# STM32G534xx register map
File version: 1.0
Registers are 32-bit, read-write, reset 0x0 unless marked. A register's access mark holds for its fields unless they carry their own. Offsets are from the block's base; [hi:lo] are bit positions; {n}, {i} and the like mark numbered series.

## DTS — Digital temperature sensor (DTS)
Base 0x40008C00
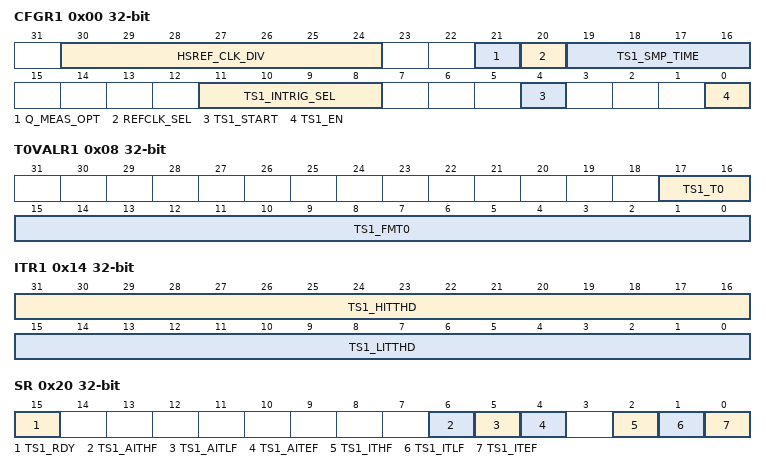
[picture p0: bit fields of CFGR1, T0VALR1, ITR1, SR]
0x00 CFGR1 — Temperature sensor configuration register 1
  [30:24] HSREF_CLK_DIV, [21] Q_MEAS_OPT, [20] REFCLK_SEL, [19:16] TS1_SMP_TIME, [11:8] TS1_INTRIG_SEL, [4] TS1_START, [0] TS1_EN
0x08 T0VALR1 ro — Temperature sensor T0 value register 1
  [17:16] TS1_T0, [15:0] TS1_FMT0
0x10 RAMPVALR ro — Temperature sensor ramp value register
  [15:0] TS1_RAMP_COEFF
0x14 ITR1 — Temperature sensor interrupt threshold register 1
  [31:16] TS1_HITTHD, [15:0] TS1_LITTHD
0x1C DR — Temperature sensor data register
  [15:0] TS1_MFREQ
0x20 SR ro — Temperature sensor status register
  [15] TS1_RDY, [6] TS1_AITHF, [5] TS1_AITLF, [4] TS1_AITEF, [2] TS1_ITHF, [1] TS1_ITLF, [0] TS1_ITEF
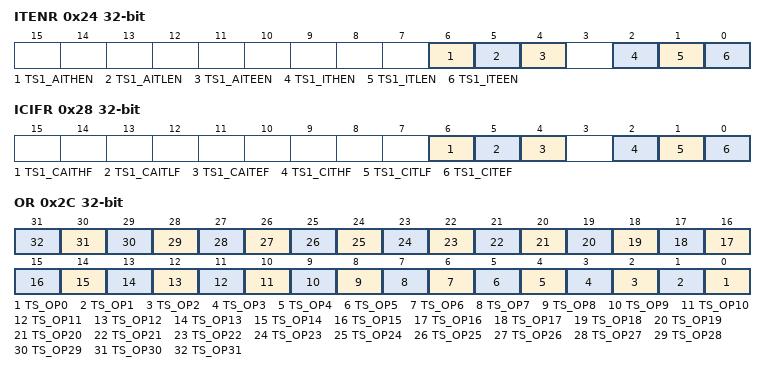
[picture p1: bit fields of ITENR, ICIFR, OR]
0x24 ITENR — Temperature sensor interrupt enable register
  [6] TS1_AITHEN, [5] TS1_AITLEN, [4] TS1_AITEEN, [2] TS1_ITHEN, [1] TS1_ITLEN, [0] TS1_ITEEN
0x28 ICIFR — Temperature sensor clear interrupt flag register
  [6] TS1_CAITHF, [5] TS1_CAITLF, [4] TS1_CAITEF, [2] TS1_CITHF, [1] TS1_CITLF, [0] TS1_CITEF
0x2C OR — Temperature sensor option register
  [n] TS_OP{n} (n=0..31) — general purpose option bits

## FDCAN_CONFIG — FD Controller Area Network Configuration
Base 0x4000A100
0x00 CKDIV — FDCAN CFG clock divider register
  [3:0] PDIV — input clock divider

## CRC — Cyclic redundancy check calculation unit (CRC)
Base 0x40023000
0x00 DR — CRC data register
  [31:0] DR — Data register bits
0x04 IDR — CRC independent data register
  [31:0] IDR — General-purpose 32-bit data register bits
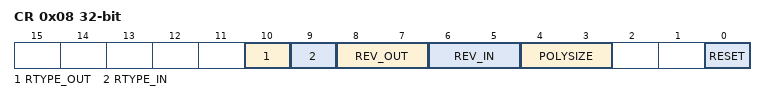
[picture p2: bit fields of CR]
0x08 CR — CRC control register
  [10] RTYPE_OUT — Reverse type output
  [9] RTYPE_IN — Reverse type input
  [8:7] REV_OUT — Reverse output data
  [6:5] REV_IN — Reverse input data
  [4:3] POLYSIZE — Polynomial size
  [0] RESET — RESET bit
0x10 INIT — CRC initial value
  [31:0] CRC_INIT — Programmable initial CRC value
0x14 POL — CRC polynomial
  [31:0] POL — Programmable polynomial

## CORDIC1 — CORDIC coprocessor (CORDIC)
Base 0x40023800
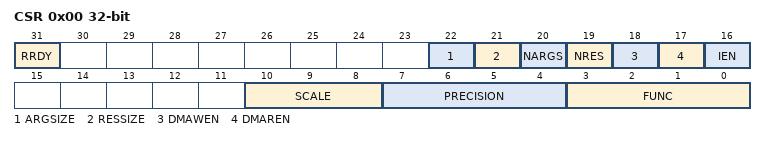
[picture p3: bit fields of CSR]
0x00 CSR — CORDIC Control and Status register
  [31] RRDY — Result ready flag
  [22] ARGSIZE — Width of input data
  [21] RESSIZE — Width of output data
  [20] NARGS
  [19] NRES
  [18] DMAWEN — Enable DMA write channel
  [17] DMAREN — Enable DMA read channel
  [16] IEN — Enable interrupt
  [10:8] SCALE — Scaling factor
  [7:4] PRECISION — Precision required (number of iterations)
  [3:0] FUNC — Function
0x04 WDATA — CORDIC argument register
  [31:0] ARG — Function input arguments
0x08 RDATA ro — CORDIC result register
  [31:0] RES — Function result

## FMAC1 — Filter math accelerator (FMAC)
Base 0x40023C00
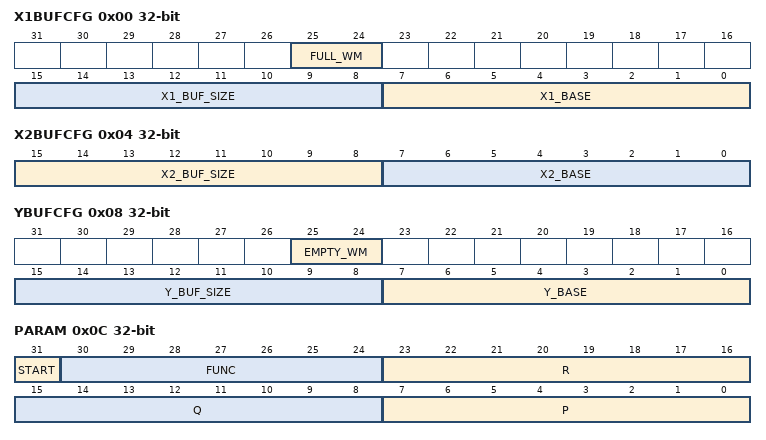
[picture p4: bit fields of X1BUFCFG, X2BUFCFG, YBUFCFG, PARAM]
0x00 X1BUFCFG — FMAC X1 buffer configuration register
  [25:24] FULL_WM — Watermark for buffer full flag
  [15:8] X1_BUF_SIZE
  [7:0] X1_BASE — Base address of X1 buffer
0x04 X2BUFCFG — FMAC X2 buffer configuration register
  [15:8] X2_BUF_SIZE
  [7:0] X2_BASE — Base address of X2 buffer
0x08 YBUFCFG — FMAC Y buffer configuration register
  [25:24] EMPTY_WM — Watermark for buffer empty flag
  [15:8] Y_BUF_SIZE
  [7:0] Y_BASE — Base address of Y buffer
0x0C PARAM — FMAC parameter register
  [31] START — Enable execution
  [30:24] FUNC — Function
  [23:16] R — Input parameter R
  [15:8] Q — Input parameter Q
  [7:0] P — Input parameter P
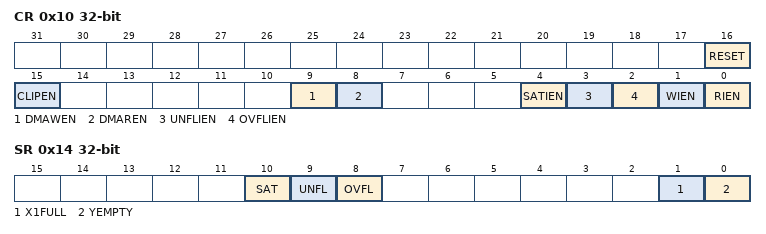
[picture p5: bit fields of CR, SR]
0x10 CR — FMAC control register
  [16] RESET — Reset FMAC unit
  [15] CLIPEN — Enable clipping
  [9] DMAWEN
  [8] DMAREN
  [4] SATIEN
  [3] UNFLIEN
  [2] OVFLIEN
  [1] WIEN — Enable write interrupt
  [0] RIEN — Enable read interrupt
0x14 SR ro — FMAC status register
  [10] SAT — Saturation error flag
  [9] UNFL — Underflow error flag
  [8] OVFL — Overflow error flag
  [1] X1FULL — X1 buffer full flag
  [0] YEMPTY — Y buffer empty flag
0x18 WDATA — FMAC write data register
  [15:0] WDATA — Write data
0x1C RDATA ro — FMAC read data register
  [15:0] RDATA — Read data
